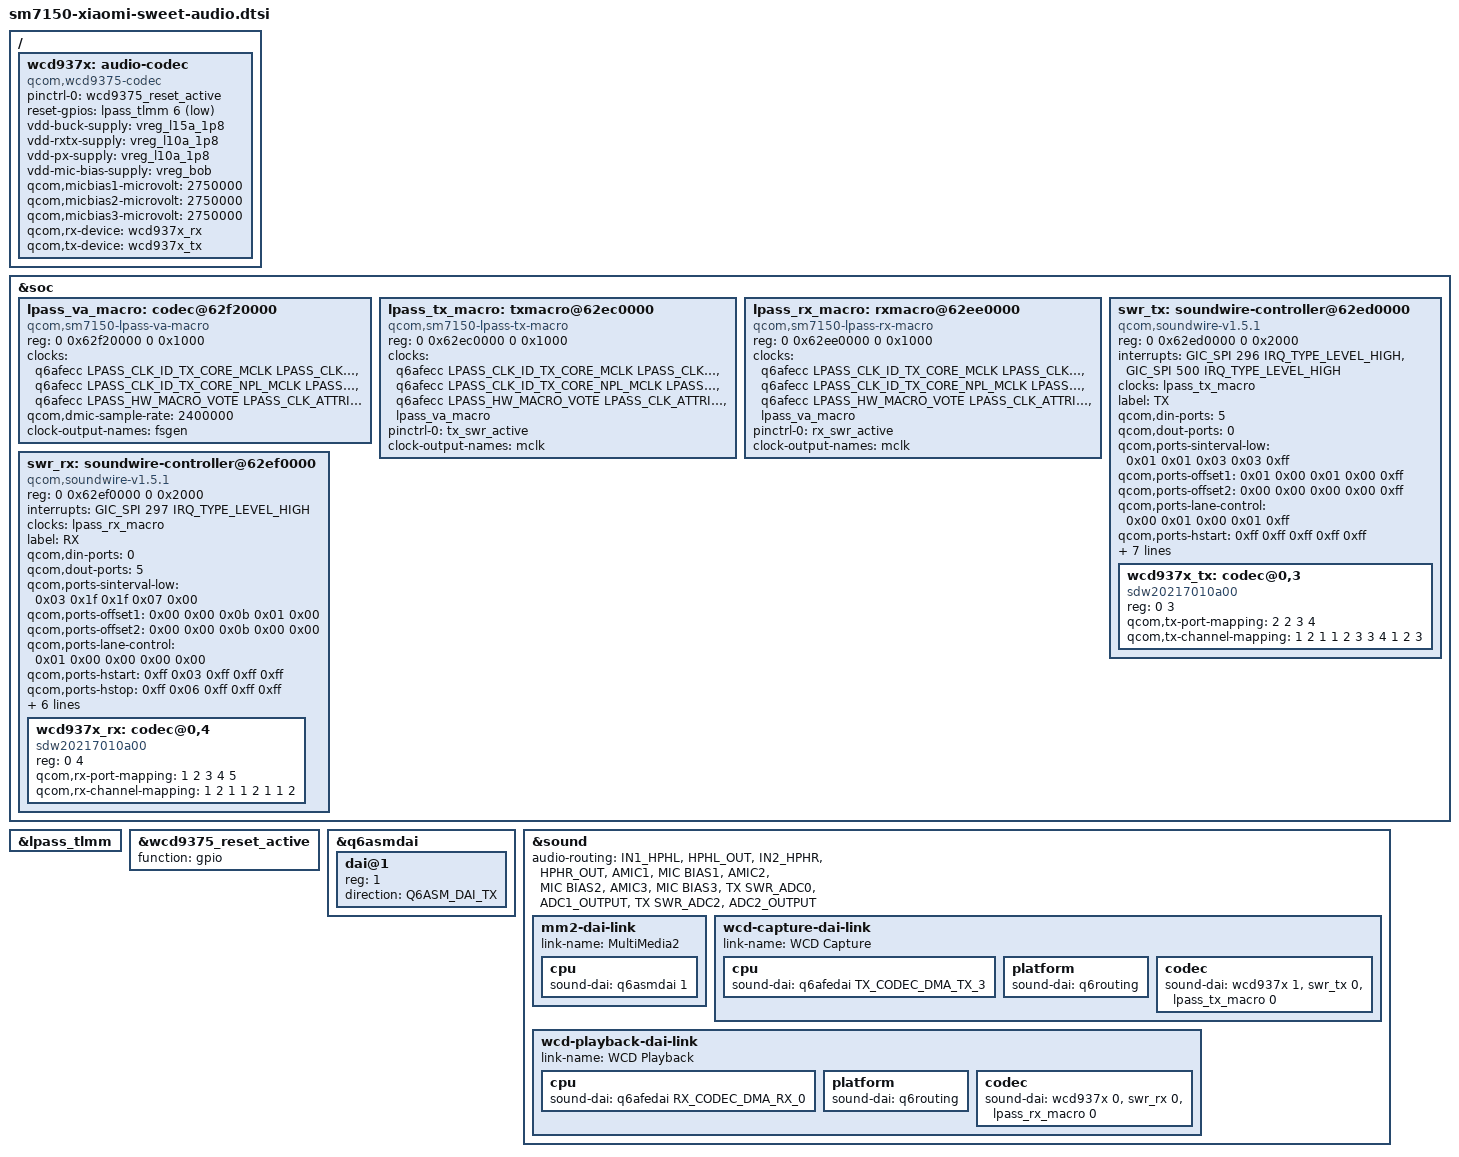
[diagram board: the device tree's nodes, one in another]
// SPDX-License-Identifier: BSD-3-Clause
/*
 * Copyright (c) 2026, j4niwzis <j4niwzis@proton.me>
 *
 * WCD9375 analog audio and LPASS SoundWire for Xiaomi sweet.
 * Controller addresses, interrupts and microphone bias follow sweet
 * downstream device tree. Port frame parameters follow its SoundWire
 * master configuration.
 */

#include <dt-bindings/sound/qcom,q6afe.h>
#include <dt-bindings/sound/qcom,q6asm.h>
#include <dt-bindings/sound/qcom,q6dsp-lpass-ports.h>

&soc {
	lpass_va_macro: codec@62f20000 {
		compatible = "qcom,sm7150-lpass-va-macro", "qcom,sm8250-lpass-va-macro";
		reg = <0 0x62f20000 0 0x1000>;

		clocks = <&q6afecc LPASS_CLK_ID_TX_CORE_MCLK LPASS_CLK_ATTRIBUTE_COUPLE_NO>,
			<&q6afecc LPASS_CLK_ID_TX_CORE_NPL_MCLK LPASS_CLK_ATTRIBUTE_COUPLE_NO>,
			<&q6afecc LPASS_HW_MACRO_VOTE LPASS_CLK_ATTRIBUTE_COUPLE_NO>;
		clock-names = "mclk", "npl", "macro";

		/* probe fails with "dt entry missing" without this */
		qcom,dmic-sample-rate = <2400000>;

		#clock-cells = <0>;
		clock-output-names = "fsgen";
		#sound-dai-cells = <1>;
	};

	lpass_tx_macro: txmacro@62ec0000 {
		compatible = "qcom,sm7150-lpass-tx-macro", "qcom,sm8250-lpass-tx-macro";
		reg = <0 0x62ec0000 0 0x1000>;

		clocks = <&q6afecc LPASS_CLK_ID_TX_CORE_MCLK LPASS_CLK_ATTRIBUTE_COUPLE_NO>,
			<&q6afecc LPASS_CLK_ID_TX_CORE_NPL_MCLK LPASS_CLK_ATTRIBUTE_COUPLE_NO>,
			<&q6afecc LPASS_HW_MACRO_VOTE LPASS_CLK_ATTRIBUTE_COUPLE_NO>,
			<&lpass_va_macro>;
		clock-names = "mclk", "npl", "macro", "fsgen";

		pinctrl-names = "default";
		pinctrl-0 = <&tx_swr_active>;

		#clock-cells = <0>;
		clock-output-names = "mclk";
		#sound-dai-cells = <1>;
	};

	lpass_rx_macro: rxmacro@62ee0000 {
		compatible = "qcom,sm7150-lpass-rx-macro", "qcom,sm8250-lpass-rx-macro";
		reg = <0 0x62ee0000 0 0x1000>;

		clocks = <&q6afecc LPASS_CLK_ID_TX_CORE_MCLK LPASS_CLK_ATTRIBUTE_COUPLE_NO>,
			<&q6afecc LPASS_CLK_ID_TX_CORE_NPL_MCLK LPASS_CLK_ATTRIBUTE_COUPLE_NO>,
			<&q6afecc LPASS_HW_MACRO_VOTE LPASS_CLK_ATTRIBUTE_COUPLE_NO>,
			<&lpass_va_macro>;
		clock-names = "mclk", "npl", "macro", "fsgen";

		pinctrl-names = "default";
		pinctrl-0 = <&rx_swr_active>;

		#clock-cells = <0>;
		clock-output-names = "mclk";
		#sound-dai-cells = <1>;
	};


	swr_tx: soundwire-controller@62ed0000 {
		compatible = "qcom,soundwire-v1.5.1";
		reg = <0 0x62ed0000 0 0x2000>;

		interrupts = <GIC_SPI 296 IRQ_TYPE_LEVEL_HIGH>,
			    <GIC_SPI 500 IRQ_TYPE_LEVEL_HIGH>;
		interrupt-names = "core", "wakeup";

		clocks = <&lpass_tx_macro>;
		clock-names = "iface";
		label = "TX";

		qcom,din-ports = <5>;
		qcom,dout-ports = <0>;

		/* downstream tx_frame_params_superset; ADC1 arrives on port 2 */
		qcom,ports-sinterval-low = /bits/ 8 <0x01 0x01 0x03 0x03 0xff>;
		qcom,ports-offset1 = /bits/ 8 <0x01 0x00 0x01 0x00 0xff>;
		qcom,ports-offset2 = /bits/ 8 <0x00 0x00 0x00 0x00 0xff>;
		qcom,ports-lane-control = /bits/ 8 <0x00 0x01 0x00 0x01 0xff>;
		qcom,ports-hstart = /bits/ 8 <0xff 0xff 0xff 0xff 0xff>;
		qcom,ports-hstop = /bits/ 8 <0xff 0xff 0xff 0xff 0xff>;
		qcom,ports-word-length = /bits/ 8 <0xff 0xff 0xff 0xff 0xff>;
		qcom,ports-block-pack-mode = /bits/ 8 <0xff 0xff 0xff 0xff 0xff>;
		qcom,ports-block-group-count = /bits/ 8 <0xff 0xff 0xff 0xff 0xff>;

		#sound-dai-cells = <1>;
		#address-cells = <2>;
		#size-cells = <0>;

		wcd937x_tx: codec@0,3 {
			compatible = "sdw20217010a00";
			reg = <0 3>;
			qcom,tx-port-mapping = <2 2 3 4>;
			qcom,tx-channel-mapping = /bits/ 8 <1 2 1 1 2 3 3 4 1 2 3>;
		};
	};

	swr_rx: soundwire-controller@62ef0000 {
		compatible = "qcom,soundwire-v1.5.1";
		reg = <0 0x62ef0000 0 0x2000>;

		interrupts = <GIC_SPI 297 IRQ_TYPE_LEVEL_HIGH>;
		clocks = <&lpass_rx_macro>;
		clock-names = "iface";
		label = "RX";

		qcom,din-ports = <0>;
		qcom,dout-ports = <5>;

		qcom,ports-sinterval-low = /bits/ 8 <0x03 0x1f 0x1f 0x07 0x00>;
		qcom,ports-offset1 = /bits/ 8 <0x00 0x00 0x0b 0x01 0x00>;
		qcom,ports-offset2 = /bits/ 8 <0x00 0x00 0x0b 0x00 0x00>;
		qcom,ports-lane-control = /bits/ 8 <0x01 0x00 0x00 0x00 0x00>;
		qcom,ports-hstart = /bits/ 8 <0xff 0x03 0xff 0xff 0xff>;
		qcom,ports-hstop = /bits/ 8 <0xff 0x06 0xff 0xff 0xff>;
		qcom,ports-word-length = /bits/ 8 <0x01 0x07 0x04 0xff 0xff>;
		qcom,ports-block-pack-mode = /bits/ 8 <0xff 0x00 0x01 0xff 0xff>;
		qcom,ports-block-group-count = /bits/ 8 <0xff 0xff 0xff 0xff 0x00>;

		#sound-dai-cells = <1>;
		#address-cells = <2>;
		#size-cells = <0>;

		wcd937x_rx: codec@0,4 {
			compatible = "sdw20217010a00";
			reg = <0 4>;
			qcom,rx-port-mapping = <1 2 3 4 5>;
			qcom,rx-channel-mapping = /bits/ 8 <1 2 1 1 2 1 1 2>;
		};
	};
};

/ {
	wcd937x: audio-codec {
		compatible = "qcom,wcd9375-codec";

		/* Keep reset deasserted during runtime clock stopping. */
		pinctrl-names = "default";
		pinctrl-0 = <&wcd9375_reset_active>;
		reset-gpios = <&lpass_tlmm 6 GPIO_ACTIVE_LOW>;

		vdd-buck-supply = <&vreg_l15a_1p8>;
		vdd-rxtx-supply = <&vreg_l10a_1p8>;
		vdd-px-supply = <&vreg_l10a_1p8>;
		vdd-mic-bias-supply = <&vreg_bob>;

		qcom,micbias1-microvolt = <2750000>;
		qcom,micbias2-microvolt = <2750000>;
		qcom,micbias3-microvolt = <2750000>;

		qcom,rx-device = <&wcd937x_rx>;
		qcom,tx-device = <&wcd937x_tx>;

		#sound-dai-cells = <1>;
	};
};

&lpass_tlmm {
	/delete-property/ gpio-reserved-ranges;

};

&wcd9375_reset_active {
	function = "gpio";
};

/* Second frontend: q6asm frontends are created from the dai@N child nodes
 * (q6asm-dai.c), and only dai@0 is described. Without its own PCM the mic
 * shares one device with the speaker and PulseAudio cannot open the
 * Speaker+Mic profile. */
&q6asmdai {
	dai@1 {
		reg = <1>;
		direction = <Q6ASM_DAI_TX>;
	};
};

&sound {
	audio-routing = "IN1_HPHL", "HPHL_OUT",
			"IN2_HPHR", "HPHR_OUT",
			"AMIC1", "MIC BIAS1",
			"AMIC2", "MIC BIAS2",
			"AMIC3", "MIC BIAS3",
			"TX SWR_ADC0", "ADC1_OUTPUT",
			"TX SWR_ADC2", "ADC2_OUTPUT";

	mm2-dai-link {
		link-name = "MultiMedia2";
		cpu {
			sound-dai = <&q6asmdai 1>;
		};
	};

	wcd-capture-dai-link {
		link-name = "WCD Capture";
		cpu {
			sound-dai = <&q6afedai TX_CODEC_DMA_TX_3>;
		};
		platform {
			sound-dai = <&q6routing>;
		};
		codec {
			sound-dai = <&wcd937x 1>, <&swr_tx 0>, <&lpass_tx_macro 0>;
		};
	};

	wcd-playback-dai-link {
		link-name = "WCD Playback";
		cpu {
			sound-dai = <&q6afedai RX_CODEC_DMA_RX_0>;
		};
		platform {
			sound-dai = <&q6routing>;
		};
		codec {
			sound-dai = <&wcd937x 0>, <&swr_rx 0>, <&lpass_rx_macro 0>;
		};
	};
};
